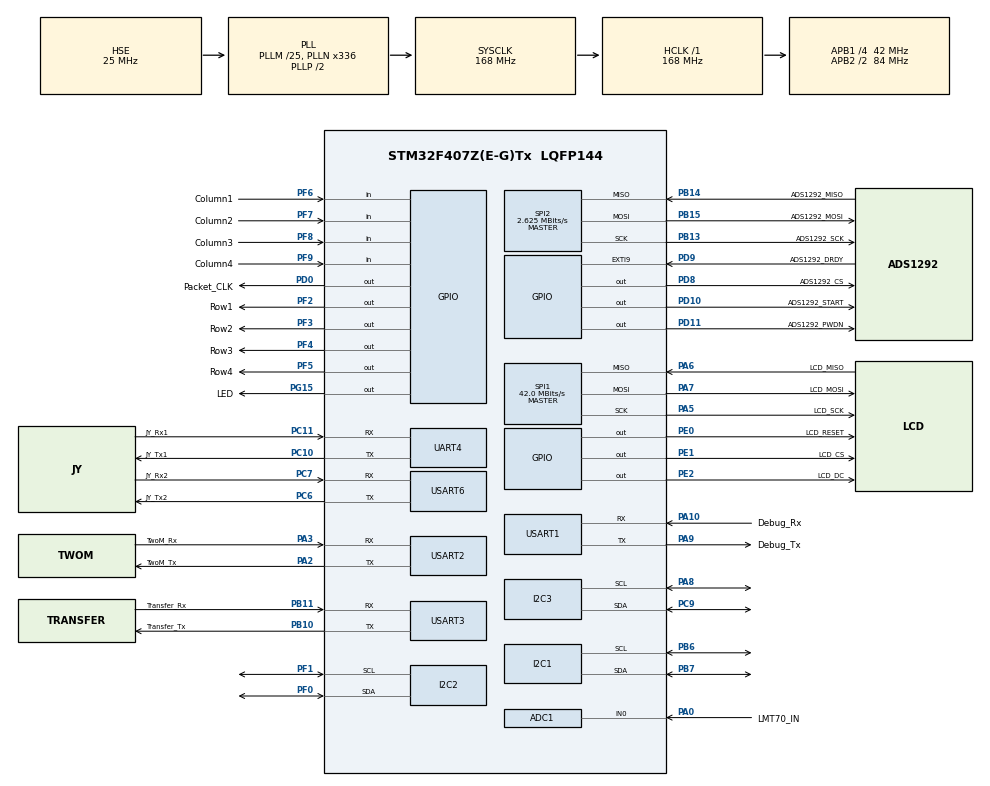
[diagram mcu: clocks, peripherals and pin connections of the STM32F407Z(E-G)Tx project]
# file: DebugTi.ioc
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ADC1.Channel-1\#ChannelRegularConversion=ADC_CHANNEL_0
ADC1.ClockPrescaler=ADC_CLOCK_SYNC_PCLK_DIV8
ADC1.NbrOfConversion=1
ADC1.NbrOfConversionFlag=1
ADC1.Rank-1\#ChannelRegularConversion=1
ADC1.SamplingTime-1\#ChannelRegularConversion=ADC_SAMPLETIME_3CYCLES
ADC1.master=1
Mcu.Family=STM32F4
Mcu.Name=STM32F407Z(E-G)Tx
Mcu.Package=LQFP144
NVIC.PriorityGroup=NVIC_PRIORITYGROUP_4
NVIC.TIM2_IRQn=true\:3\:0\:true\:false\:true\:true\:true
NVIC.USART1_IRQn=true\:1\:0\:true\:false\:true\:true\:true
NVIC.USART2_IRQn=true\:2\:0\:true\:false\:true\:true\:true
PA0-WKUP.GPIO_Label=LMT70_IN
PA0-WKUP.Signal=ADCx_IN0
PA10.GPIO_Label=Debug_Rx
PA10.Mode=Asynchronous
PA10.Signal=USART1_RX
PA13.Mode=Serial_Wire
PA13.Signal=SYS_JTMS-SWDIO
PA14.Mode=Serial_Wire
PA14.Signal=SYS_JTCK-SWCLK
PA2.GPIO_Label=TwoM_Tx
PA2.Mode=Asynchronous
PA2.Signal=USART2_TX
PA3.GPIO_Label=TwoM_Rx
PA3.Mode=Asynchronous
PA3.Signal=USART2_RX
PA5.GPIO_Label=LCD_SCK
PA5.Mode=Full_Duplex_Master
PA5.Signal=SPI1_SCK
PA6.GPIO_Label=LCD_MISO
PA6.Mode=Full_Duplex_Master
PA6.Signal=SPI1_MISO
PA7.GPIO_Label=LCD_MOSI
PA7.Mode=Full_Duplex_Master
PA7.Signal=SPI1_MOSI
PA8.Mode=I2C
PA8.Signal=I2C3_SCL
PA9.GPIO_Label=Debug_Tx
PA9.Mode=Asynchronous
PA9.Signal=USART1_TX
PB10.GPIO_Label=Transfer_Tx
PB10.Mode=Asynchronous
PB10.Signal=USART3_TX
PB11.GPIO_Label=Transfer_Rx
PB11.Mode=Asynchronous
PB11.Signal=USART3_RX
PB13.GPIO_Label=ADS1292_SCK
PB13.Mode=Full_Duplex_Master
PB13.Signal=SPI2_SCK
PB14.GPIO_Label=ADS1292_MISO
PB14.Mode=Full_Duplex_Master
PB14.Signal=SPI2_MISO
PB15.GPIO_Label=ADS1292_MOSI
PB15.Mode=Full_Duplex_Master
PB15.Signal=SPI2_MOSI
PB6.Mode=I2C
PB6.Signal=I2C1_SCL
PB7.Mode=I2C
PB7.Signal=I2C1_SDA
PC10.GPIO_Label=JY_Tx1
PC10.Mode=Asynchronous
PC10.Signal=UART4_TX
PC11.GPIO_Label=JY_Rx1
PC11.Mode=Asynchronous
PC11.Signal=UART4_RX
PC6.GPIO_Label=JY_Tx2
PC6.Mode=Asynchronous
PC6.Signal=USART6_TX
PC7.GPIO_Label=JY_Rx2
PC7.Mode=Asynchronous
PC7.Signal=USART6_RX
PC9.Mode=I2C
PC9.Signal=I2C3_SDA
PD0.GPIO_Label=Packet_CLK
PD0.GPIO_PuPd=GPIO_NOPULL
PD0.GPIO_Speed=GPIO_SPEED_FREQ_VERY_HIGH
PD0.PinState=GPIO_PIN_RESET
PD0.Signal=GPIO_Output
PD10.GPIO_Label=ADS1292_START
PD10.Signal=GPIO_Output
PD11.GPIO_Label=ADS1292_PWDN
PD11.Signal=GPIO_Output
PD8.GPIO_Label=ADS1292_CS
PD8.Signal=GPIO_Output
PD9.GPIO_Label=ADS1292_DRDY
PD9.GPIO_ModeDefaultEXTI=GPIO_MODE_IT_FALLING
PD9.GPIO_PuPd=GPIO_PULLUP
PD9.Signal=GPXTI9
PE0.GPIO_Label=LCD_RESET
PE0.GPIO_ModeDefaultOutputPP=GPIO_MODE_OUTPUT_PP
PE0.GPIO_PuPd=GPIO_PULLUP
PE0.GPIO_Speed=GPIO_SPEED_FREQ_LOW
PE0.PinState=GPIO_PIN_SET
PE0.Signal=GPIO_Output
PE1.GPIO_Label=LCD_CS
PE1.GPIO_ModeDefaultOutputPP=GPIO_MODE_OUTPUT_PP
PE1.GPIO_PuPd=GPIO_PULLUP
PE1.GPIO_Speed=GPIO_SPEED_FREQ_LOW
PE1.PinState=GPIO_PIN_SET
PE1.Signal=GPIO_Output
PE2.GPIO_Label=LCD_DC
PE2.GPIO_ModeDefaultOutputPP=GPIO_MODE_OUTPUT_PP
PE2.GPIO_PuPd=GPIO_PULLUP
PE2.GPIO_Speed=GPIO_SPEED_FREQ_LOW
PE2.PinState=GPIO_PIN_SET
PE2.Signal=GPIO_Output
PF0.Mode=I2C
PF0.Signal=I2C2_SDA
PF1.Mode=I2C
PF1.Signal=I2C2_SCL
PF2.GPIO_Label=Row1
PF2.GPIO_PuPd=GPIO_PULLUP
PF2.PinState=GPIO_PIN_SET
PF2.Signal=GPIO_Output
PF3.GPIO_Label=Row2
PF3.GPIO_ModeDefaultOutputPP=GPIO_MODE_OUTPUT_PP
PF3.GPIO_PuPd=GPIO_PULLUP
PF3.GPIO_Speed=GPIO_SPEED_FREQ_LOW
PF3.PinState=GPIO_PIN_SET
PF3.Signal=GPIO_Output
PF4.GPIO_Label=Row3
PF4.GPIO_ModeDefaultOutputPP=GPIO_MODE_OUTPUT_PP
PF4.GPIO_PuPd=GPIO_PULLUP
PF4.GPIO_Speed=GPIO_SPEED_FREQ_LOW
PF4.PinState=GPIO_PIN_SET
PF4.Signal=GPIO_Output
PF5.GPIO_Label=Row4
PF5.GPIO_ModeDefaultOutputPP=GPIO_MODE_OUTPUT_PP
PF5.GPIO_PuPd=GPIO_PULLUP
PF5.GPIO_Speed=GPIO_SPEED_FREQ_LOW
PF5.PinState=GPIO_PIN_SET
PF5.Signal=GPIO_Output
PF6.GPIO_Label=Column1
PF6.GPIO_PuPd=GPIO_PULLUP
PF6.Signal=GPIO_Input
PF7.GPIO_Label=Column2
PF7.GPIO_Mode=GPIO_MODE_INPUT
PF7.GPIO_PuPd=GPIO_PULLUP
PF7.Signal=GPIO_Input
PF8.GPIO_Label=Column3
PF8.GPIO_Mode=GPIO_MODE_INPUT
PF8.GPIO_PuPd=GPIO_PULLUP
PF8.Signal=GPIO_Input
PF9.GPIO_Label=Column4
PF9.GPIO_Mode=GPIO_MODE_INPUT
PF9.GPIO_PuPd=GPIO_PULLUP
PF9.Signal=GPIO_Input
PG15.GPIO_Label=LED
PG15.GPIO_ModeDefaultOutputPP=GPIO_MODE_OUTPUT_PP
PG15.GPIO_PuPd=GPIO_NOPULL
PG15.PinState=GPIO_PIN_SET
PG15.Signal=GPIO_Output
PH0-OSC_IN.Mode=HSE-External-Oscillator
PH0-OSC_IN.Signal=RCC_OSC_IN
PH1-OSC_OUT.Mode=HSE-External-Oscillator
PH1-OSC_OUT.Signal=RCC_OSC_OUT
ProjectManager.HeapSize=0x1000
ProjectManager.StackSize=0x1000
ProjectManager.TargetToolchain=MDK-ARM V5.27
RCC.48MHZClocksFreq_Value=48000000
RCC.AHBFreq_Value=168000000
RCC.APB1CLKDivider=RCC_HCLK_DIV4
RCC.APB1Freq_Value=42000000
RCC.APB1TimFreq_Value=84000000
RCC.APB2CLKDivider=RCC_HCLK_DIV2
RCC.APB2Freq_Value=84000000
RCC.APB2TimFreq_Value=168000000
RCC.CortexFreq_Value=168000000
RCC.HCLKFreq_Value=168000000
RCC.HSE_VALUE=25000000
RCC.HSI_VALUE=16000000
RCC.LSE_VALUE=32768
RCC.PLLM=25
RCC.PLLN=336
RCC.PLLQ=7
RCC.PLLSourceVirtual=RCC_PLLSOURCE_HSE
RCC.SYSCLKFreq_VALUE=168000000
RCC.SYSCLKSource=RCC_SYSCLKSOURCE_PLLCLK
RCC.VCOOutputFreq_Value=336000000
SH.ADCx_IN0.0=ADC1_IN0,IN0
SPI1.CLKPhase=SPI_PHASE_2EDGE
SPI1.CLKPolarity=SPI_POLARITY_HIGH
SPI1.CalculateBaudRate=42.0 MBits/s
SPI1.Direction=SPI_DIRECTION_2LINES
SPI1.Mode=SPI_MODE_MASTER
SPI1.VirtualType=VM_MASTER
SPI2.BaudRatePrescaler=SPI_BAUDRATEPRESCALER_16
SPI2.CLKPhase=SPI_PHASE_2EDGE
SPI2.CalculateBaudRate=2.625 MBits/s
SPI2.DataSize=SPI_DATASIZE_8BIT
SPI2.Direction=SPI_DIRECTION_2LINES
SPI2.Mode=SPI_MODE_MASTER
SPI2.VirtualType=VM_MASTER
TIM2.Period=99
TIM2.Prescaler=8399
UART4.VirtualMode=Asynchronous
USART1.VirtualMode=VM_ASYNC
USART2.VirtualMode=VM_ASYNC
USART3.VirtualMode=VM_ASYNC
USART6.VirtualMode=VM_ASYNC
VP_TIM2_VS_ClockSourceINT.Mode=Internal
board=custom

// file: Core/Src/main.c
/* USER CODE BEGIN Header */
/**
  ******************************************************************************
  * @file           : main.c
  * @brief          : Main program body
  ******************************************************************************
  * @attention
  *
  * <h2><center>&copy; Copyright (c) 2020 STMicroelectronics.
  * All rights reserved.</center></h2>
  *
  * This software component is licensed by ST under BSD 3-Clause license,
  * the "License"; You may not use this file except in compliance with the
  * License. You may obtain a copy of the License at:
  *                        opensource.org/licenses/BSD-3-Clause
  *
  ******************************************************************************
  */
/* USER CODE END Header */
#include "main.h"
#include "adc.h"
#include "i2c.h"
#include "spi.h"
#include "tim.h"
#include "usart.h"
#include "gpio.h"

/* USER CODE BEGIN Includes */
#include "UserMain.h"
/* USER CODE END Includes */

void SystemClock_Config(void);

int main(void)
{

  /* MCU Configuration--------------------------------------------------------*/

  /* Reset of all peripherals, Initializes the Flash interface and the Systick. */
  HAL_Init();

  /* Configure the system clock */
  SystemClock_Config();

  /* Initialize all configured peripherals */
  MX_GPIO_Init();
  MX_ADC1_Init();
  MX_I2C1_Init();
  MX_TIM2_Init();
  MX_USART1_UART_Init();
  MX_SPI1_Init();
  MX_USART2_UART_Init();
  MX_SPI2_Init();
  MX_USART3_UART_Init();
  MX_I2C2_Init();
  MX_UART4_Init();
  MX_USART6_UART_Init();
  MX_I2C3_Init();
  /* USER CODE BEGIN 2 */
  UserInit();
  /* USER CODE END 2 */

  /* Infinite loop */
  /* USER CODE BEGIN WHILE */
  while (1)
  {
	  UserMain();
    /* USER CODE END WHILE */

  }
}

void SystemClock_Config(void)
{
  RCC_OscInitTypeDef RCC_OscInitStruct = {0};
  RCC_ClkInitTypeDef RCC_ClkInitStruct = {0};

  /** Configure the main internal regulator output voltage
  */
  __HAL_RCC_PWR_CLK_ENABLE();
  __HAL_PWR_VOLTAGESCALING_CONFIG(PWR_REGULATOR_VOLTAGE_SCALE1);
  /** Initializes the RCC Oscillators according to the specified parameters
  * in the RCC_OscInitTypeDef structure.
  */
  RCC_OscInitStruct.OscillatorType = RCC_OSCILLATORTYPE_HSE;
  RCC_OscInitStruct.HSEState = RCC_HSE_ON;
  RCC_OscInitStruct.PLL.PLLState = RCC_PLL_ON;
  RCC_OscInitStruct.PLL.PLLSource = RCC_PLLSOURCE_HSE;
  RCC_OscInitStruct.PLL.PLLM = 25;
  RCC_OscInitStruct.PLL.PLLN = 336;
  RCC_OscInitStruct.PLL.PLLP = RCC_PLLP_DIV2;
  RCC_OscInitStruct.PLL.PLLQ = 7;
  if (HAL_RCC_OscConfig(&RCC_OscInitStruct) != HAL_OK)
  {
    Error_Handler();
  }
  /** Initializes the CPU, AHB and APB buses clocks
  */
  RCC_ClkInitStruct.ClockType = RCC_CLOCKTYPE_HCLK|RCC_CLOCKTYPE_SYSCLK
                              |RCC_CLOCKTYPE_PCLK1|RCC_CLOCKTYPE_PCLK2;
  RCC_ClkInitStruct.SYSCLKSource = RCC_SYSCLKSOURCE_PLLCLK;
  RCC_ClkInitStruct.AHBCLKDivider = RCC_SYSCLK_DIV1;
  RCC_ClkInitStruct.APB1CLKDivider = RCC_HCLK_DIV4;
  RCC_ClkInitStruct.APB2CLKDivider = RCC_HCLK_DIV2;

  if (HAL_RCC_ClockConfig(&RCC_ClkInitStruct, FLASH_LATENCY_5) != HAL_OK)
  {
    Error_Handler();
  }
}

void Error_Handler(void)
{
}

/************************ (C) COPYRIGHT STMicroelectronics *****END OF FILE****/
